VERSION ""

NS_ :

BS_:

BU_:

BO_ 17 New_Message_18: 8 Vector__XXX
 SG_ New_Signal_63 : 16|8@1+ (1,0) [0|0] "" Vector__XXX

BO_ 16 New_Message_17: 8 Vector__XXX
 SG_ New_Signal_62 : 24|8@1+ (1,0) [0|0] "" Vector__XXX

BO_ 15 New_Message_16: 8 Vector__XXX
 SG_ New_Signal_53 : 23|8@1+ (1,0) [0|0] "" Vector__XXX

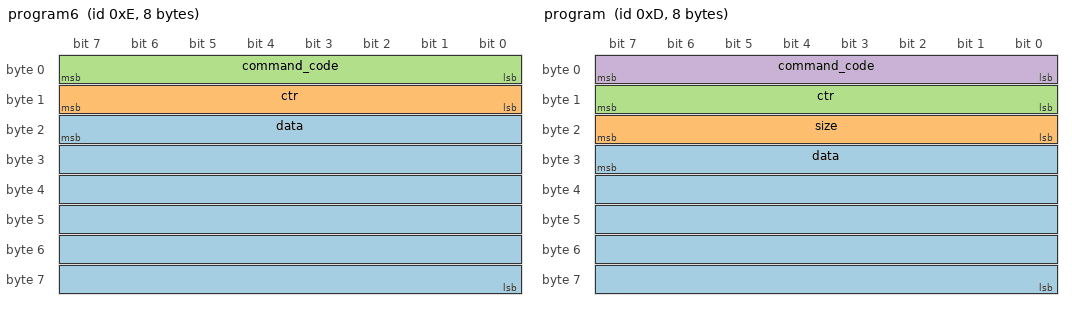
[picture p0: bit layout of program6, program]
BO_ 14 program6: 8 Vector__XXX
 SG_ data : 23|48@0+ (1,0) [0|0] "" Vector__XXX
 SG_ ctr : 8|8@1+ (1,0) [0|0] "" Vector__XXX
 SG_ command_code : 0|8@1+ (1,0) [0|0] "" Vector__XXX

BO_ 13 program: 8 Vector__XXX
 SG_ data : 31|40@0+ (1,0) [0|0] "" Vector__XXX
 SG_ size : 16|8@1+ (1,0) [0|0] "" Vector__XXX
 SG_ ctr : 8|8@1+ (1,0) [0|0] "" Vector__XXX
 SG_ command_code : 0|8@1+ (1,0) [0|0] "" Vector__XXX

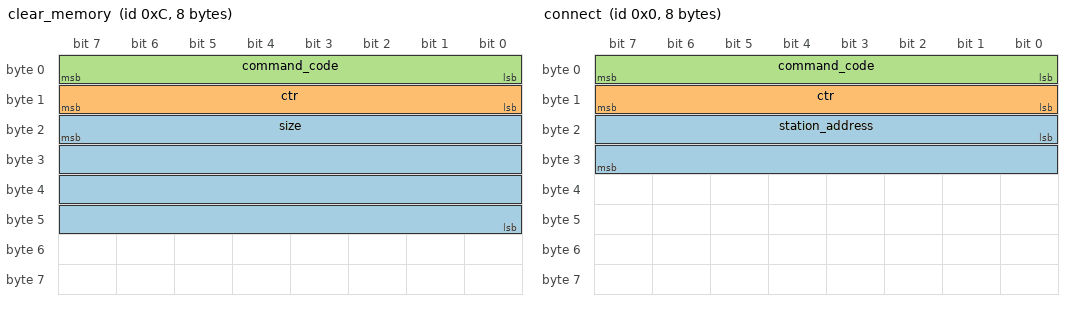
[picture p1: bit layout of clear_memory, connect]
BO_ 12 clear_memory: 8 Vector__XXX
 SG_ size : 23|32@0+ (1,0) [0|0] "" Vector__XXX
 SG_ ctr : 8|8@1+ (1,0) [0|0] "" Vector__XXX
 SG_ command_code : 0|8@1+ (1,0) [0|0] "" Vector__XXX

BO_ 0 connect: 8 Vector__XXX
 SG_ station_address : 16|16@1+ (1,0) [0|0] "" Vector__XXX
 SG_ ctr : 8|8@1+ (1,0) [0|0] "" Vector__XXX
 SG_ command_code : 0|8@1+ (1,0) [0|0] "" Vector__XXX

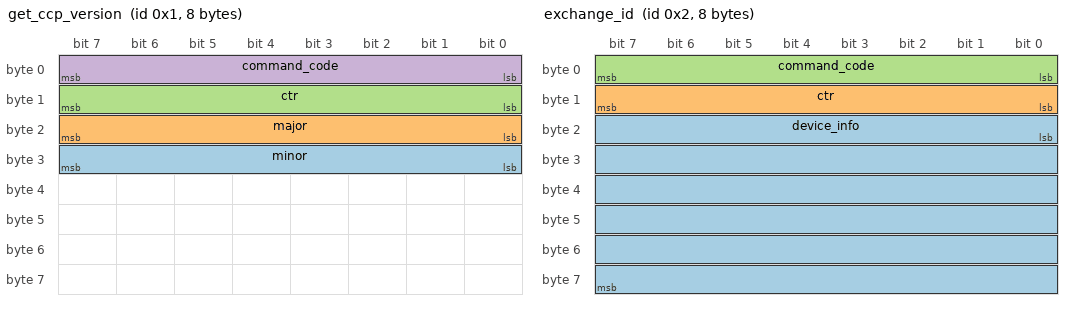
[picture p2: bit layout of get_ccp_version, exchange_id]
BO_ 1 get_ccp_version: 8 Vector__XXX
 SG_ minor : 24|8@1+ (1,0) [0|0] "" Vector__XXX
 SG_ major : 16|8@1+ (1,0) [0|0] "" Vector__XXX
 SG_ ctr : 8|8@1+ (1,0) [0|0] "" Vector__XXX
 SG_ command_code : 0|8@1+ (1,0) [0|0] "" Vector__XXX

BO_ 2 exchange_id: 8 Vector__XXX
 SG_ device_info : 16|48@1+ (1,0) [0|0] "" Vector__XXX
 SG_ ctr : 8|8@1+ (1,0) [0|0] "" Vector__XXX
 SG_ command_code : 0|8@1+ (1,0) [0|0] "" Vector__XXX

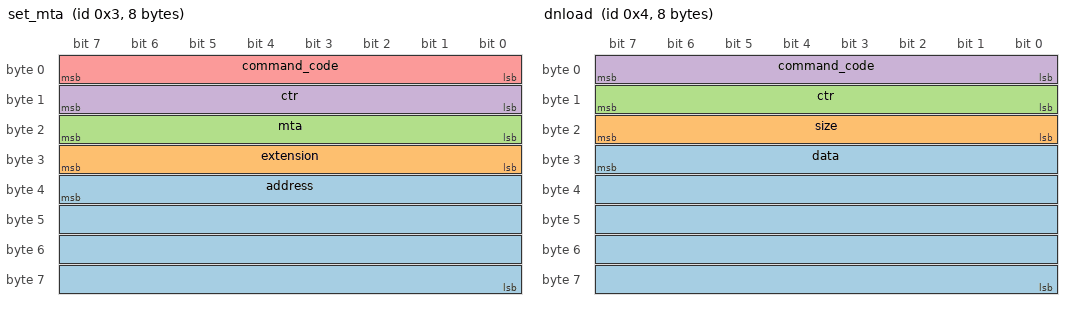
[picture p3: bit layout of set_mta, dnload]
BO_ 3 set_mta: 8 Vector__XXX
 SG_ address : 39|32@0+ (1,0) [0|0] "" Vector__XXX
 SG_ extension : 24|8@1+ (1,0) [0|0] "" Vector__XXX
 SG_ mta : 16|8@1+ (1,0) [0|0] "" Vector__XXX
 SG_ ctr : 8|8@1+ (1,0) [0|0] "" Vector__XXX
 SG_ command_code : 0|8@1+ (1,0) [0|0] "" Vector__XXX

BO_ 4 dnload: 8 Vector__XXX
 SG_ data : 31|40@0+ (1,0) [0|0] "" Vector__XXX
 SG_ size : 16|8@1+ (1,0) [0|0] "" Vector__XXX
 SG_ ctr : 8|8@1+ (1,0) [0|0] "" Vector__XXX
 SG_ command_code : 0|8@1+ (1,0) [0|0] "" Vector__XXX

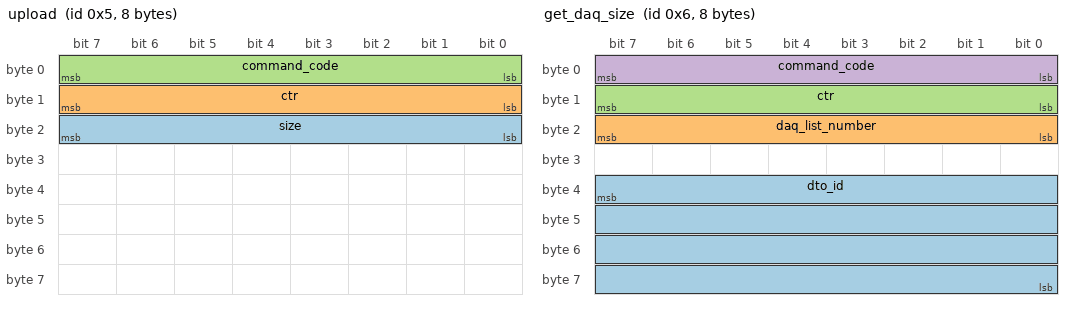
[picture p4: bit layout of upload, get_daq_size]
BO_ 5 upload: 8 Vector__XXX
 SG_ size : 16|8@1+ (1,0) [0|0] "" Vector__XXX
 SG_ ctr : 8|8@1+ (1,0) [0|0] "" Vector__XXX
 SG_ command_code : 0|8@1+ (1,0) [0|0] "" Vector__XXX

BO_ 6 get_daq_size: 8 Vector__XXX
 SG_ dto_id : 39|32@0+ (1,0) [0|0] "" Vector__XXX
 SG_ daq_list_number : 16|8@1+ (1,0) [0|0] "" Vector__XXX
 SG_ ctr : 8|8@1+ (1,0) [0|0] "" Vector__XXX
 SG_ command_code : 0|8@1+ (1,0) [0|0] "" Vector__XXX

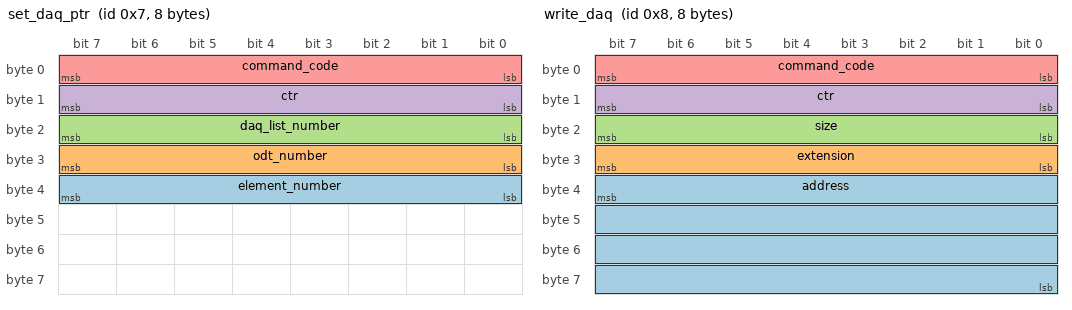
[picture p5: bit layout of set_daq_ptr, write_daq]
BO_ 7 set_daq_ptr: 8 Vector__XXX
 SG_ element_number : 32|8@1+ (1,0) [0|0] "" Vector__XXX
 SG_ odt_number : 24|8@1+ (1,0) [0|0] "" Vector__XXX
 SG_ daq_list_number : 16|8@1+ (1,0) [0|0] "" Vector__XXX
 SG_ ctr : 8|8@1+ (1,0) [0|0] "" Vector__XXX
 SG_ command_code : 0|8@1+ (1,0) [0|0] "" Vector__XXX

BO_ 8 write_daq: 8 Vector__XXX
 SG_ address : 39|32@0+ (1,0) [0|0] "" Vector__XXX
 SG_ extension : 24|8@1+ (1,0) [0|0] "" Vector__XXX
 SG_ size : 16|8@1+ (1,0) [0|0] "" Vector__XXX
 SG_ ctr : 8|8@1+ (1,0) [0|0] "" Vector__XXX
 SG_ command_code : 0|8@1+ (1,0) [0|0] "" Vector__XXX

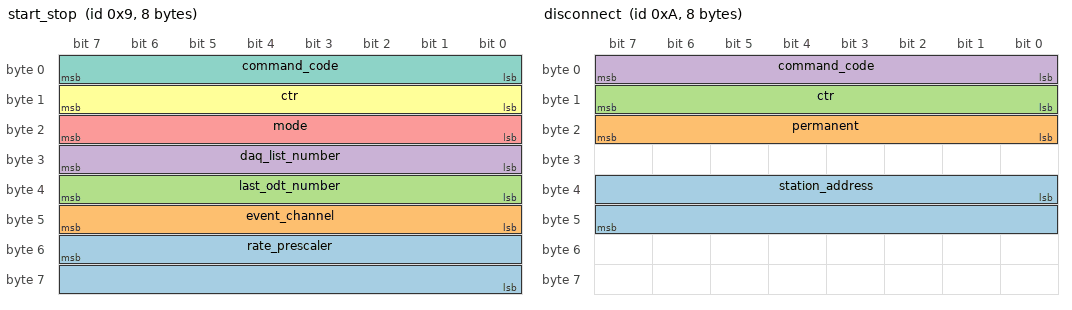
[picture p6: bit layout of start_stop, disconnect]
BO_ 9 start_stop: 8 Vector__XXX
 SG_ rate_prescaler : 55|16@0+ (1,0) [0|0] "" Vector__XXX
 SG_ event_channel : 40|8@1+ (1,0) [0|0] "" Vector__XXX
 SG_ last_odt_number : 32|8@1+ (1,0) [0|0] "" Vector__XXX
 SG_ daq_list_number : 24|8@1+ (1,0) [0|0] "" Vector__XXX
 SG_ mode : 16|8@1+ (1,0) [0|0] "" Vector__XXX
 SG_ ctr : 8|8@1+ (1,0) [0|0] "" Vector__XXX
 SG_ command_code : 0|8@1+ (1,0) [0|0] "" Vector__XXX

BO_ 10 disconnect: 8 Vector__XXX
 SG_ station_address : 32|16@1+ (1,0) [0|0] "" Vector__XXX
 SG_ permanent : 16|8@1+ (1,0) [0|0] "" Vector__XXX
 SG_ ctr : 8|8@1+ (1,0) [0|0] "" Vector__XXX
 SG_ command_code : 0|8@1+ (1,0) [0|0] "" Vector__XXX

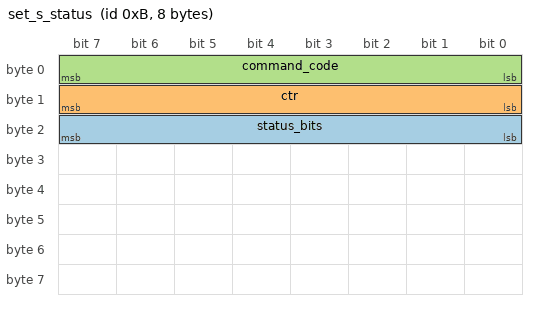
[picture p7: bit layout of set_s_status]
BO_ 11 set_s_status: 8 Vector__XXX
 SG_ status_bits : 16|8@1+ (1,0) [0|0] "" Vector__XXX
 SG_ ctr : 8|8@1+ (1,0) [0|0] "" Vector__XXX
 SG_ command_code : 0|8@1+ (1,0) [0|0] "" Vector__XXX
